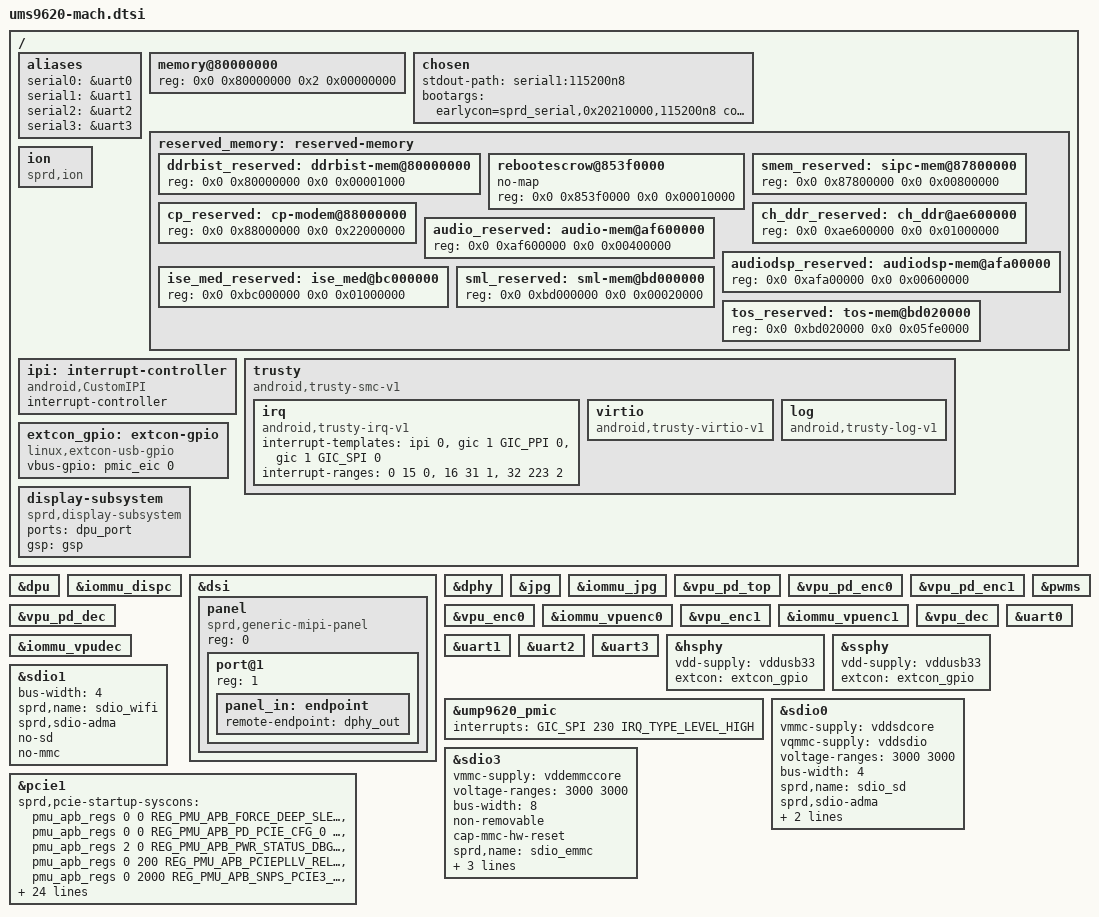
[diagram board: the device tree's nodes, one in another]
/*
 * Spreadtrum Qogirn6pro board common DTS file
 *
 * Copyright (C) 2020, Spreadtrum Communications Inc.
 *
 * This file is licensed under a dual GPLv2 or X11 license.
 */

#include "ump9620.dtsi"

/{

	aliases {
		serial0 = &uart0;
		serial1 = &uart1;
		serial2 = &uart2;
		serial3 = &uart3;
	};

	memory@80000000 {
		device_type = "memory";
		reg = <0x0 0x80000000 0x2 0x00000000>;
	};

	chosen: chosen {
		stdout-path = "serial1:115200n8";
		bootargs = "earlycon=sprd_serial,0x20210000,115200n8 console=ttyS1,115200n8 loglevel=1 init=/init root=/dev/ram0 rw printk.devkmsg=on androidboot.selinux=permissive pcie_ports=compat";
	};

	reserved_memory: reserved-memory {
		#address-cells = <2>;
		#size-cells = <2>;
		ranges;

		ddrbist_reserved: ddrbist-mem@80000000 {
			reg = <0x0 0x80000000 0x0 0x00001000>;
		};

		rebootescrow@853f0000 {
			no-map;
			reg = <0x0 0x853f0000 0x0 0x00010000>; /* 64K */
		};

		smem_reserved: sipc-mem@87800000 {
			reg = <0x0 0x87800000 0x0 0x00800000>;
		};

		cp_reserved: cp-modem@88000000 {
			reg = <0x0 0x88000000 0x0 0x22000000>;
		};

		ch_ddr_reserved: ch_ddr@ae600000 {
			reg = <0x0 0xae600000 0x0 0x01000000>;
		};

		audio_reserved: audio-mem@af600000 {
			reg = <0x0 0xaf600000 0x0 0x00400000>;
		};

		audiodsp_reserved: audiodsp-mem@afa00000 {
			reg = <0x0 0xafa00000 0x0 0x00600000>;
		};

		ise_med_reserved: ise_med@bc000000 {
			reg = <0x0 0xbc000000 0x0 0x01000000>;
		};

		/* must be 1M aligned */
		sml_reserved: sml-mem@bd000000 {
			reg = <0x0 0xbd000000 0x0 0x00020000>;
		};

		tos_reserved: tos-mem@bd020000 {
			reg = <0x0 0xbd020000 0x0 0x05fe0000>;
		};

	};

	ion: ion {
		compatible = "sprd,ion";
		#address-cells = <1>;
		#size-cells = <0>;
	};

	ipi: interrupt-controller {
		compatible = "android,CustomIPI";
		#interrupt-cells = <1>;
		interrupt-controller;
	};

	trusty {
		compatible = "android,trusty-smc-v1";
		irq {
			compatible = "android,trusty-irq-v1";
			interrupt-templates = <&ipi 0>,
						<&gic 1 GIC_PPI 0>,
						<&gic 1 GIC_SPI 0>;
				interrupt-ranges = < 0  15 0>,
						<16  31 1>,
						<32 223 2>;
		};

		virtio {
			compatible = "android,trusty-virtio-v1";
		};

		log {
			compatible = "android,trusty-log-v1";
		};
	};

        extcon_gpio: extcon-gpio {
		compatible = "linux,extcon-usb-gpio";
		vbus-gpio = <&pmic_eic 0 GPIO_ACTIVE_HIGH>;
	};

	display-subsystem {
		compatible = "sprd,display-subsystem";
		ports = <&dpu_port>;
		gsp = <&gsp>;
	};
};

&dpu {
	status = "okay";
};

&iommu_dispc {
	status = "okay";
};

&dsi {
	status = "okay";
	#address-cells = <1>;
	#size-cells = <0>;

	panel: panel {
		compatible = "sprd,generic-mipi-panel";
		#address-cells = <1>;
		#size-cells = <0>;
		reg = <0>;

		port@1 {
			reg = <1>;
			panel_in: endpoint {
				remote-endpoint = <&dphy_out>;
			};
		};
	};
};

&dphy {
	status = "okay";
};

&jpg {
	status = "okay";
};

&iommu_jpg {
	status = "okay";
};

&vpu_pd_top {
	status = "okay";
};

&vpu_pd_enc0 {
	status = "okay";
};

&vpu_pd_enc1 {
	status = "okay";
};

&vpu_pd_dec {
	status = "okay";
};

&vpu_enc0 {
	status = "okay";
};

&iommu_vpuenc0 {
	status = "okay";
};

&vpu_enc1 {
	status = "okay";
};

&iommu_vpuenc1 {
	status = "okay";
};

&vpu_dec {
	status = "okay";
};

&iommu_vpudec {
	status = "okay";
};

&pwms {
	status = "okay";
};

&uart0 {
	status = "okay";
};

&uart1 {
	status = "okay";
};

&uart2 {
	status = "okay";
};

&uart3 {
	status = "okay";
};

&hsphy {
	vdd-supply = <&vddusb33>;
	extcon = <&extcon_gpio>;
	status = "okay";
};

&ssphy {
	vdd-supply = <&vddusb33>;
	extcon = <&extcon_gpio>;
	status = "okay";
};

&ump9620_pmic {
	interrupts = <GIC_SPI 230 IRQ_TYPE_LEVEL_HIGH>;
};

&sdio0 {
	vmmc-supply = <&vddsdcore>;
	vqmmc-supply = <&vddsdio>;
	voltage-ranges = <3000 3000>;
	bus-width = <4>;
	sprd,name = "sdio_sd";
	sprd,sdio-adma;
	no-sdio;
	no-mmc;
	status = "okay";
};

&sdio1 {
	bus-width = <4>;
	sprd,name = "sdio_wifi";
	sprd,sdio-adma;
	no-sd;
	no-mmc;
	status = "okay";
};

&sdio3 {
	vmmc-supply = <&vddemmccore>;
	voltage-ranges = <3000 3000>;
	bus-width = <8>;
	non-removable;
	cap-mmc-hw-reset;
	sprd,name = "sdio_emmc";
	sprd,sdio-adma;
	no-sdio;
	no-sd;
	status = "okay";
};

&pcie1 {
		sprd,pcie-startup-syscons =
		/* Not force PCIe DEEP SLEEP */
		<&pmu_apb_regs 0 0
			REG_PMU_APB_FORCE_DEEP_SLEEP_CFG_0
			MASK_PMU_APB_PCIE_FORCE_DEEP_SLEEP_REG
			0x0>,
		/* power up */
		<&pmu_apb_regs 0 0
			REG_PMU_APB_PD_PCIE_CFG_0
			MASK_PMU_APB_PD_PCIE_FORCE_SHUTDOWN
			0x0>,
		/* check power state */
		<&pmu_apb_regs 2 0
			REG_PMU_APB_PWR_STATUS_DBG_22
			MASK_PMU_APB_PD_PCIE_STATE
			0x0>,
		/*
		 * Remain 100M reference clock to active at least 200us to make
		 * sure that it's stable before pulling high perst#.
		 */
		<&pmu_apb_regs 0 200
			REG_PMU_APB_PCIEPLLV_REL_CFG
			MASK_PMU_APB_PCIEPLLV_FRC_ON
			0x1>,
		/* perst assert */
		<&pmu_apb_regs 0 2000
			REG_PMU_APB_SNPS_PCIE3_SLP_CTRL
			MASK_PMU_APB_REG_PERST_N_ASSERT
			0x0>,
		/* PCIEPLLV output clock will be gated for L1sub */
		<&pmu_apb_regs 0 0
			REG_PMU_APB_SNPS_PCIE3_SLP_CTRL
			MASK_PMU_APB_PCIE_CLK_REQ_PLL_GATE_MASK
			0x0>;

	sprd,pcie-resume-syscons =
		<&pmu_apb_regs 0 0
			REG_PMU_APB_PD_PCIE_CFG_0
			MASK_PMU_APB_PD_PCIE_FORCE_SHUTDOWN
			0x0>,
		<&pmu_apb_regs 2 0
			REG_PMU_APB_PWR_STATUS_DBG_22
			MASK_PMU_APB_PD_PCIE_STATE
			0x0>,
		<&pmu_apb_regs 0 200
			REG_PMU_APB_PCIEPLLV_REL_CFG
			MASK_PMU_APB_PCIEPLLV_FRC_ON
			0x1>,
		/* pcie eb */
		<&pcie_apb_regs 0 200
			0x4 /* no corresponding macro */
			0x80
			0x80>,
		<&pmu_apb_regs 0 2000
			REG_PMU_APB_SNPS_PCIE3_SLP_CTRL
			MASK_PMU_APB_REG_PERST_N_ASSERT
			0x0>;

	sprd,pcie-suspend-syscons =
		<&pmu_apb_regs 0 0
			REG_PMU_APB_SNPS_PCIE3_SLP_CTRL
			MASK_PMU_APB_REG_PERST_N_ASSERT
			0x2>,
		<&aon_apb_regs 0 0
			REG_AON_APB_IPA_ACCESS_CFG
			MASK_AON_APB_AON_ACCESS_PCIE_EN
			0x2>,
		/*disable pcie eb */
		<&pcie_apb_regs 0 200
			0x4
			0x80
			0x0>,
		<&aon_apb_regs 0 0
			REG_AON_APB_IPA_ACCESS_CFG
			MASK_AON_APB_AON_ACCESS_PCIE_EN
			0x0>,
		/* PCIEPLLV will be shutdown after ipa_deep_sleep */
		<&pmu_apb_regs 0 0
			REG_PMU_APB_PCIEPLLV_REL_CFG
			MASK_PMU_APB_PCIEPLLV_IPA_SEL
			0x0>,
		<&pmu_apb_regs 0 0
			REG_PMU_APB_PCIEPLLV_REL_CFG
			MASK_PMU_APB_PCIEPLLV_FRC_ON
			0x0>,
		/* power down */
		<&pmu_apb_regs 0 0
			REG_PMU_APB_PD_PCIE_CFG_0
			MASK_PMU_APB_PD_PCIE_FORCE_SHUTDOWN
			0x2000000>;

	sprd,pcie-shutdown-syscons =
		<&pmu_apb_regs 0 0
			REG_PMU_APB_SNPS_PCIE3_SLP_CTRL
			MASK_PMU_APB_REG_PERST_N_ASSERT
			0x2>,
		<&aon_apb_regs 0 0
			REG_AON_APB_IPA_ACCESS_CFG
			MASK_AON_APB_AON_ACCESS_PCIE_EN
			0x2>,
		/*disable pcie eb */
		<&pcie_apb_regs 0 200
			0x4
			0x80
			0x0>,
		<&aon_apb_regs 0 0
			REG_AON_APB_IPA_ACCESS_CFG
			MASK_AON_APB_AON_ACCESS_PCIE_EN
			0x0>,
		/* PCIEPLLV will be shutdown after ipa_deep_sleep */
		<&pmu_apb_regs 0 0
			REG_PMU_APB_PCIEPLLV_REL_CFG
			MASK_PMU_APB_PCIEPLLV_IPA_SEL
			0x0>,
		<&pmu_apb_regs 0 0
			REG_PMU_APB_PCIEPLLV_REL_CFG
			MASK_PMU_APB_PCIEPLLV_FRC_ON
			0x0>,
		/* power down */
		<&pmu_apb_regs 0 0
			REG_PMU_APB_PD_PCIE_CFG_0
			MASK_PMU_APB_PD_PCIE_FORCE_SHUTDOWN
			0x2000000>;

	ep-poweron-late;
	status = "okay";
};

